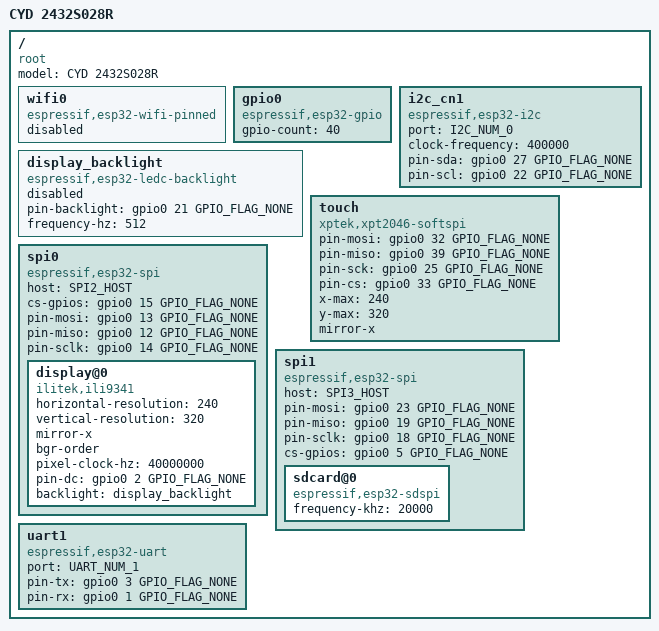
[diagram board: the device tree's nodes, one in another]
/dts-v1/;

#include <tactility/bindings/root.h>
#include <tactility/bindings/esp32_wifi_pinned.h>
#include <tactility/bindings/esp32_gpio.h>
#include <tactility/bindings/esp32_i2c.h>
#include <tactility/bindings/esp32_spi.h>
#include <tactility/bindings/esp32_uart.h>
#include <tactility/bindings/esp32_sdspi.h>
#include <tactility/bindings/esp32_ledc_backlight.h>
#include <bindings/ili9341.h>
#include <bindings/xpt2046_softspi.h>

/ {
	compatible = "root";
	model = "CYD 2432S028R";

	wifi0 {
		compatible = "espressif,esp32-wifi-pinned";
		status = "disabled";
	};

	gpio0 {
		compatible = "espressif,esp32-gpio";
		gpio-count = <40>;
	};

	i2c_cn1 {
		compatible = "espressif,esp32-i2c";
		port = <I2C_NUM_0>;
		clock-frequency = <400000>;
		pin-sda = <&gpio0 27 GPIO_FLAG_NONE>;
		pin-scl = <&gpio0 22 GPIO_FLAG_NONE>;
	};

	display_backlight {
		compatible = "espressif,esp32-ledc-backlight";
		// Off by default so display power-on won't show the screen from before the last power loss.
		// The display backlight is turned on during the boot process.
		status = "disabled";
		pin-backlight = <&gpio0 21 GPIO_FLAG_NONE>;
		frequency-hz = <512>;
	};

	touch {
		compatible = "xptek,xpt2046-softspi";
		pin-mosi = <&gpio0 32 GPIO_FLAG_NONE>;
		pin-miso = <&gpio0 39 GPIO_FLAG_NONE>;
		pin-sck = <&gpio0 25 GPIO_FLAG_NONE>;
		pin-cs = <&gpio0 33 GPIO_FLAG_NONE>;
		x-max = <240>;
		y-max = <320>;
		mirror-x;
	};

	spi0 {
		compatible = "espressif,esp32-spi";
		host = <SPI2_HOST>;
		cs-gpios = <&gpio0 15 GPIO_FLAG_NONE>;
		pin-mosi = <&gpio0 13 GPIO_FLAG_NONE>;
		pin-miso = <&gpio0 12 GPIO_FLAG_NONE>;
		pin-sclk = <&gpio0 14 GPIO_FLAG_NONE>;

		display@0 {
			compatible = "ilitek,ili9341";
			horizontal-resolution = <240>;
			vertical-resolution = <320>;
			mirror-x;
			bgr-order;
			pixel-clock-hz = <40000000>;
			pin-dc = <&gpio0 2 GPIO_FLAG_NONE>;
			backlight = <&display_backlight>;
		};
	};

	spi1 {
		compatible = "espressif,esp32-spi";
		host = <SPI3_HOST>;
		pin-mosi = <&gpio0 23 GPIO_FLAG_NONE>;
		pin-miso = <&gpio0 19 GPIO_FLAG_NONE>;
		pin-sclk = <&gpio0 18 GPIO_FLAG_NONE>;
		cs-gpios = <&gpio0 5 GPIO_FLAG_NONE>;

		sdcard@0 {
			compatible = "espressif,esp32-sdspi";
			frequency-khz = <20000>;
		};
	};

	uart1 {
		compatible = "espressif,esp32-uart";
		port = <UART_NUM_1>;
		pin-tx = <&gpio0 3 GPIO_FLAG_NONE>;
		pin-rx = <&gpio0 1 GPIO_FLAG_NONE>;
	};
};
